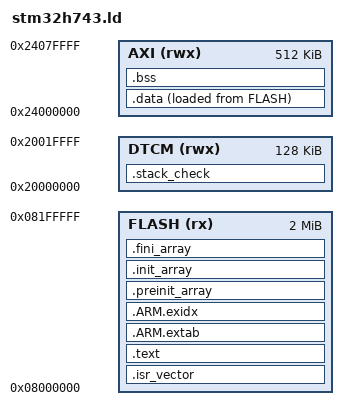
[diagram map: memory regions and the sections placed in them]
/* STM32H743ZI (NUCLEO-H743ZI2) memory map, minimal bare-metal layout.
 *   FLASH   2 MB   code and constants
 *   DTCM  128 KB   stack (zero-wait-state, core-coupled)
 *   AXI   512 KB   .data / .bss (the controller and its HPIPM arena live here)
 */
ENTRY(Reset_Handler)

MEMORY
{
  FLASH (rx)  : ORIGIN = 0x08000000, LENGTH = 2048K
  DTCM  (rwx) : ORIGIN = 0x20000000, LENGTH = 128K
  AXI   (rwx) : ORIGIN = 0x24000000, LENGTH = 512K
}

_estack = ORIGIN(DTCM) + LENGTH(DTCM);
_min_stack = 16K;

SECTIONS
{
  .isr_vector :
  {
    . = ALIGN(4);
    KEEP(*(.isr_vector))
  } > FLASH

  .text :
  {
    . = ALIGN(4);
    *(.text*)
    *(.rodata*)
    KEEP(*(.init))
    KEEP(*(.fini))
    . = ALIGN(4);
  } > FLASH

  .ARM.extab : { *(.ARM.extab* .gnu.linkonce.armextab.*) } > FLASH
  .ARM.exidx : { __exidx_start = .; *(.ARM.exidx*) __exidx_end = .; } > FLASH

  .preinit_array : { PROVIDE_HIDDEN(__preinit_array_start = .); KEEP(*(.preinit_array*)) PROVIDE_HIDDEN(__preinit_array_end = .); } > FLASH
  .init_array    : { PROVIDE_HIDDEN(__init_array_start = .); KEEP(*(SORT(.init_array.*))) KEEP(*(.init_array*)) PROVIDE_HIDDEN(__init_array_end = .); } > FLASH
  .fini_array    : { PROVIDE_HIDDEN(__fini_array_start = .); KEEP(*(SORT(.fini_array.*))) KEEP(*(.fini_array*)) PROVIDE_HIDDEN(__fini_array_end = .); } > FLASH

  _sidata = LOADADDR(.data);
  .data :
  {
    . = ALIGN(8);
    _sdata = .;
    *(.data*)
    . = ALIGN(8);
    _edata = .;
  } > AXI AT> FLASH

  .bss (NOLOAD) :
  {
    . = ALIGN(8);
    _sbss = .;
    *(.bss*)
    *(COMMON)
    . = ALIGN(8);
    _ebss = .;
    end = .;            /* newlib heap start (unused by the controller) */
  } > AXI

  .stack_check (NOLOAD) :
  {
    . = ALIGN(8);
    . = . + _min_stack;
  } > DTCM

}
